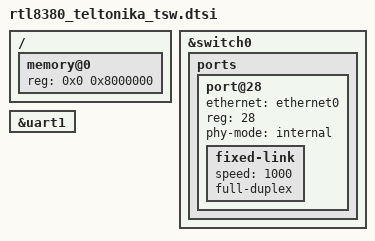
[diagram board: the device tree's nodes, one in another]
// SPDX-License-Identifier: GPL-2.0-or-later

#include "rtl838x.dtsi"

#include <dt-bindings/input/input.h>
#include <dt-bindings/gpio/gpio.h>

/ {

	memory@0 {
		device_type = "memory";
		reg = <0x0 0x8000000>;
	};

};

&switch0 {
	ports {
		#address-cells = <1>;
		#size-cells = <0>;

		port@28 {
			ethernet = <&ethernet0>;
			reg = <28>;
			phy-mode = "internal";
			fixed-link {
				speed = <1000>;
				full-duplex;
			};
		};
	};
};

&uart1 {
	status = "okay";
};
